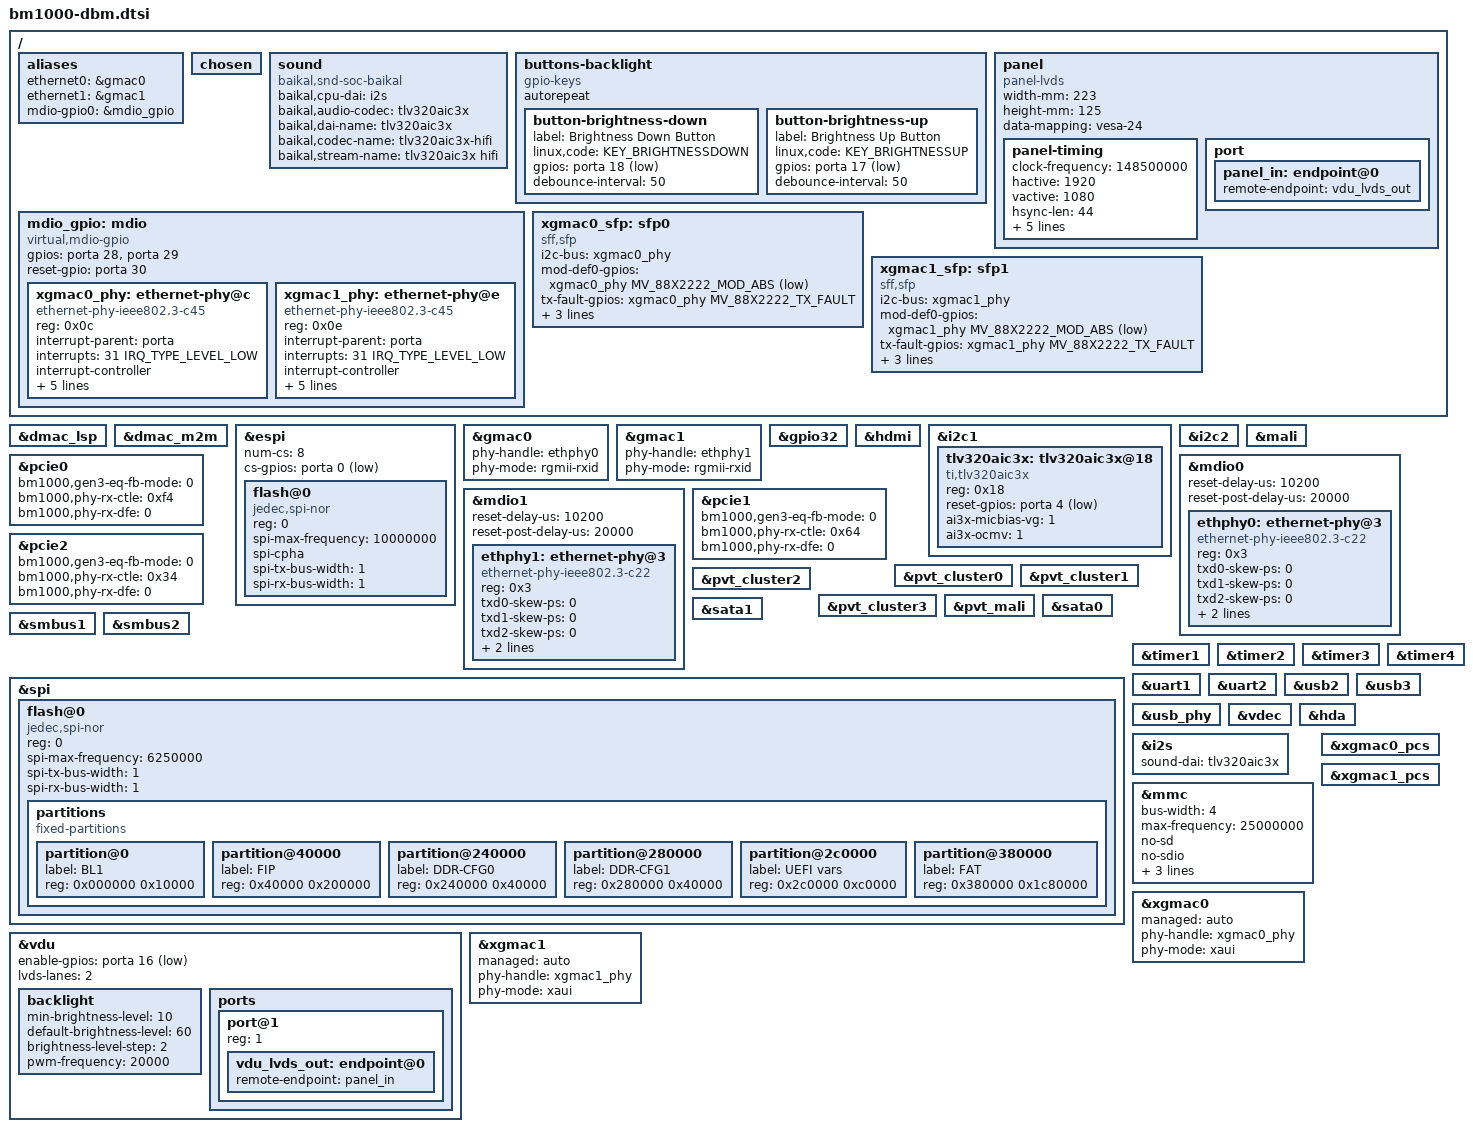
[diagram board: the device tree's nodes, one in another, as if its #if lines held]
// SPDX-License-Identifier: GPL-2.0
/*
 * Device tree source for Baikal Electronics DBM boards
 * Copyright (C) 2019-2026 Baikal Electronics, JSC
 */

#include <dt-bindings/input/input.h>
#include "bm1000.dtsi"

/ {
	aliases {
		ethernet0 = &gmac0;
		ethernet1 = &gmac1;
	};

	chosen { };
};

&dmac_lsp {
	status = "okay";
};

&dmac_m2m {
	status = "okay";
};

&espi {
	status = "okay";
	num-cs = <8>;
	cs-gpios = <&porta 0 GPIO_ACTIVE_LOW>;

	flash@0 { /* espi-test0 */
		compatible = "jedec,spi-nor";
		reg = <0>;
		#address-cells = <1>;
		#size-cells = <1>;
		spi-max-frequency = <10000000>;
		spi-cpha;
		spi-tx-bus-width = <1>;
		spi-rx-bus-width = <1>;
		status = "okay";
	};
};

&gmac0 {
	status = "okay";
	phy-handle = <&ethphy0>;
	phy-mode = "rgmii-rxid";
};

&gmac1 {
	status = "okay";
	phy-handle = <&ethphy1>;
	phy-mode = "rgmii-rxid";
};

&gpio32 {
	status = "okay";
};

&hdmi {
	status = "okay";
};

&i2c1 {
	status = "okay";
};

&i2c2 {
	status = "okay";
};

&mali {
	status = "okay";
};

&mdio0 {
	reset-delay-us = <10200>;
	/* Due to a 10uf capacitor on a reset line */
	reset-post-delay-us = <20000>;

	ethphy0: ethernet-phy@3 {
		compatible = "ethernet-phy-ieee802.3-c22";
		reg = <0x3>;
		txd0-skew-ps = <0>;
		txd1-skew-ps = <0>;
		txd2-skew-ps = <0>;
		txd3-skew-ps = <0>;
		txc-skew-ps = <0xff>;
	};
};

&mdio1 {
	reset-delay-us = <10200>;
	/* Due to a 10uf capacitor on a reset line */
	reset-post-delay-us = <20000>;

	ethphy1: ethernet-phy@3 {
		compatible = "ethernet-phy-ieee802.3-c22";
		reg = <0x3>;
		txd0-skew-ps = <0>;
		txd1-skew-ps = <0>;
		txd2-skew-ps = <0>;
		txd3-skew-ps = <0>;
		txc-skew-ps = <0xff>;
	};
};

&pcie0 {
	status = "okay";
	bm1000,gen3-eq-fb-mode = <0>;
	bm1000,phy-rx-ctle = <0xf4>;
	bm1000,phy-rx-dfe = <0>;
};

&pcie1 {
	status = "okay";
	bm1000,gen3-eq-fb-mode = <0>;
	bm1000,phy-rx-ctle = <0x64>;
	bm1000,phy-rx-dfe = <0>;
};

&pcie2 {
	status = "okay";
	bm1000,gen3-eq-fb-mode = <0>;
	bm1000,phy-rx-ctle = <0x34>;
	bm1000,phy-rx-dfe = <0>;
};

&pvt_cluster0 {
	status = "okay";
};

&pvt_cluster1 {
	status = "okay";
};

&pvt_cluster2 {
	status = "okay";
};

&pvt_cluster3 {
	status = "okay";
};

&pvt_mali {
	status = "okay";
};

&sata0 {
	status = "okay";
};

&sata1 {
	status = "okay";
};

&smbus1 {
	status = "okay";
};

&smbus2 {
	status = "okay";
};

&spi {
	status = "okay";

	flash@0 {
		compatible = "jedec,spi-nor";
		reg = <0>;
		spi-max-frequency = <6250000>;
		spi-tx-bus-width = <1>;
		spi-rx-bus-width = <1>;
		status = "okay";

		partitions {
			compatible = "fixed-partitions";
			#address-cells = <1>;
			#size-cells = <1>;

			partition@0 {
				label = "BL1";
				reg = <0x000000 0x10000>;
			};

			partition@40000 {
				label = "FIP";
				reg = <0x40000 0x200000>;
			};

			partition@240000 {
				label = "DDR-CFG0";
				reg = <0x240000 0x40000>;
			};

			partition@280000 {
				label = "DDR-CFG1";
				reg = <0x280000 0x40000>;
			};

			partition@2c0000 {
				label = "UEFI vars";
				reg = <0x2c0000 0xc0000>;
			};

			partition@380000 {
				label = "FAT";
				reg = <0x380000 0x1c80000>;
			};
		};
	};
};

&timer1 {
	status = "okay";
};

&timer2 {
	status = "okay";
};

&timer3 {
	status = "okay";
};

&timer4 {
	status = "okay";
};

&uart1 {
	status = "okay";
};

&uart2 {
	status = "okay";
};

&usb2 {
	status = "okay";
};

&usb3 {
	status = "okay";
};

&usb_phy {
	status = "okay";
};

&vdec {
	status = "okay";
};

&vdu {
	status = "okay";
};

/**************************************************/
/* Audio/SD/eMMC/LVDS expansion (mezzanine) board */
/**************************************************/
/ {
#ifdef USE_I2S
	sound {
		compatible = "baikal,snd-soc-baikal";
		baikal,cpu-dai = <&i2s>;
		baikal,audio-codec = <&tlv320aic3x>;
		baikal,dai-name = "tlv320aic3x";
		baikal,codec-name = "tlv320aic3x-hifi";
		baikal,stream-name = "tlv320aic3x hifi";
	};
#endif

#ifdef USE_LVDS
	buttons-backlight {
		compatible = "gpio-keys";
		autorepeat;
		button-brightness-down {
			label = "Brightness Down Button";
			linux,code = <KEY_BRIGHTNESSDOWN>;
			gpios = <&porta 18 GPIO_ACTIVE_LOW>;
			debounce-interval = <50>;
		};
		button-brightness-up {
			label = "Brightness Up Button";
			linux,code = <KEY_BRIGHTNESSUP>;
			gpios = <&porta 17 GPIO_ACTIVE_LOW>;
			debounce-interval = <50>;
		};
	};

	panel {
		compatible = "panel-lvds";
		width-mm = <223>;
		height-mm = <125>;
		data-mapping = "vesa-24";
		/*
		 * In order to utilize LVDS LCD panel, make sure that
		 * 'status' is "okay" along with &vdu 'status' (see below).
		 */
		status = "okay";
		panel-timing {
			/* 1920x1080 @ 60 Hz */
			/* Replace values below with actual panel timings */
			clock-frequency = <148500000>;
			hactive = <1920>;
			vactive = <1080>;
			hsync-len = <44>;
			hfront-porch = <88>;
			hback-porch = <148>;
			vsync-len = <5>;
			vfront-porch = <4>;
			vback-porch = <36>;
		};
		port {
			panel_in: endpoint@0 {
				remote-endpoint = <&vdu_lvds_out>;
			};
		};
	};
#endif
};

#ifdef USE_HDA
&hda {
	status = "okay";
};
#endif

#ifdef USE_I2S
&i2c1 {
	tlv320aic3x: tlv320aic3x@18 {
		compatible = "ti,tlv320aic3x";
		reg = <0x18>;
		#sound-dai-cells = <0>;
		reset-gpios = <&porta 4 GPIO_ACTIVE_LOW>;
		ai3x-micbias-vg = <1>;
		ai3x-ocmv = <1>;
		status = "okay";
	};
};

&i2s {
	status = "okay";
	sound-dai = <&tlv320aic3x>;
};
#endif

#ifdef USE_EMMC
&mmc {
	/* eMMC */
	status = "okay";
	bus-width = <8>;
	max-frequency = <200000000>;
	no-sd;
	no-sdio;
	non-removable;
};
#endif

#ifdef USE_SD
&mmc {
	/* SD */
	status = "okay";
	bus-width = <4>;
	max-frequency = <25000000>;
	disable-wp;
	no-mmc;
	no-sdio;
};
#endif

#ifdef USE_LVDS
&vdu {
	/*
	 * 'lvds-lanes' property is mandatory to enable LVDS. Valid values are 1, 2 or 4.
	 * It is also mandatory to provide actual values for 'enable-gpios' property.
	 * Also make sure that panel's 'status' (see above) is "okay".
	 */
	enable-gpios = <&porta 16 GPIO_ACTIVE_LOW>;
	lvds-lanes = <2>;
	backlight {
		min-brightness-level = <10>;
		default-brightness-level = <60>;
		brightness-level-step = <2>;
		pwm-frequency = <20000>;
	};
	ports {
		port@1 {
			reg = <1>;
			vdu_lvds_out: endpoint@0 {
				remote-endpoint = <&panel_in>;
			};
		};
	};
};
#endif

/*******************************************/
/* XGbE KR/KX4 expansion (mezzanine) board */
/*******************************************/
#ifdef USE_KRKX4

#include <dt-bindings/net/mv-phy-88x2222.h>

/ {
	aliases {
		mdio-gpio0 = &mdio_gpio;
	};

	mdio_gpio: mdio {
		compatible = "virtual,mdio-gpio";
		#address-cells = <1>;
		#size-cells = <0>;
		gpios = <&porta 28 GPIO_ACTIVE_HIGH>,
			<&porta 29 GPIO_ACTIVE_HIGH>;
		reset-gpio = <&porta 30 GPIO_ACTIVE_HIGH>;
		status = "okay";

		xgmac0_phy: ethernet-phy@c {
			compatible = "ethernet-phy-ieee802.3-c45";
			reg = <0x0c>;
			interrupt-parent = <&porta>;
			interrupts = <31 IRQ_TYPE_LEVEL_LOW>;
			interrupt-controller;
			#interrupt-cells = <2>;
			gpio-controller; /* 12 pins */
			#gpio-cells = <2>;
			gpio-reserved-ranges = <MV_88X2222_LED0 1>,
					       <MV_88X2222_LED1 1>,
					       <MV_88X2222_SDA 1>,
					       <MV_88X2222_SCL 1>;
			sfp = <&xgmac0_sfp>;
		};

		xgmac1_phy: ethernet-phy@e {
			compatible = "ethernet-phy-ieee802.3-c45";
			reg = <0x0e>;
			interrupt-parent = <&porta>;
			interrupts = <31 IRQ_TYPE_LEVEL_LOW>;
			interrupt-controller;
			#interrupt-cells = <2>;
			gpio-controller; /* 12 pins */
			#gpio-cells = <2>;
			gpio-reserved-ranges = <MV_88X2222_LED0 1>,
					       <MV_88X2222_LED1 1>,
					       <MV_88X2222_SDA 1>,
					       <MV_88X2222_SCL 1>;
			sfp = <&xgmac1_sfp>;
		};
	};

	xgmac0_sfp: sfp0 {
		compatible = "sff,sfp";
		i2c-bus = <&xgmac0_phy>;
		mod-def0-gpios = <&xgmac0_phy MV_88X2222_MOD_ABS GPIO_ACTIVE_LOW>;
		tx-fault-gpios = <&xgmac0_phy MV_88X2222_TX_FAULT GPIO_ACTIVE_HIGH>;
		los-gpios = <&xgmac0_phy MV_88X2222_RX_LOS GPIO_ACTIVE_HIGH>;
		tx-disable-gpios = <&xgmac0_phy MV_88X2222_TX_DISABLE GPIO_ACTIVE_HIGH>;
	};

	xgmac1_sfp: sfp1 {
		compatible = "sff,sfp";
		i2c-bus = <&xgmac1_phy>;
		mod-def0-gpios = <&xgmac1_phy MV_88X2222_MOD_ABS GPIO_ACTIVE_LOW>;
		tx-fault-gpios = <&xgmac1_phy MV_88X2222_TX_FAULT GPIO_ACTIVE_HIGH>;
		los-gpios = <&xgmac1_phy MV_88X2222_RX_LOS GPIO_ACTIVE_HIGH>;
		tx-disable-gpios = <&xgmac1_phy MV_88X2222_TX_DISABLE GPIO_ACTIVE_HIGH>;
	};
};

&xgmac0 {
	managed = "auto";
	phy-handle = <&xgmac0_phy>;
	phy-mode = "xaui";
	status = "okay";
};

&xgmac0_pcs {
	status = "okay";
};

&xgmac1 {
	managed = "auto";
	phy-handle = <&xgmac1_phy>;
	phy-mode = "xaui";
	status = "okay";
};

&xgmac1_pcs {
	status = "okay";
};

#endif /* USE_KRKX4 */
